VERSION ""

NS_ :

BS_:

BU_: DataECU UDSnode04 UDSnode03 MyECU

BO_ 514 msg_com_data2_CAN2: 8 DataECU
 SG_ sig_com_data2_CAN2 : 0|64@1+ (1,0) [0|1.84467440737096E+019] ""  MyECU

BO_ 513 msg_com_data1_CAN2: 8 DataECU
 SG_ sig_com_data1_CAN2 : 0|64@1+ (1,0) [0|1.84467440737096E+019] ""  MyECU

BO_ 1632 msg_diag_response_UDSnode04: 8 UDSnode04
 SG_ sig_diag_response_UDSnode04 : 0|8@1+ (1,0) [0|255] ""  MyECU

BO_ 1616 msg_diag_response_UDSnode03: 8 UDSnode03
 SG_ sig_diag_response_UDSnode03 : 0|8@1+ (1,0) [0|255] ""  MyECU

BO_ 1634 msg_diag_request_UDSnode04: 8 MyECU
 SG_ sig_diag_request_UDSnode04 : 0|8@1+ (1,0) [0|255] ""  UDSnode04

BO_ 1618 msg_diag_request_UDSnode03: 8 MyECU
 SG_ sig_diag_request_UDSnode03 : 0|8@1+ (1,0) [0|255] ""  UDSnode03

BO_ 1790 msg_diag_request_func_CAN2: 8 MyECU
 SG_ sig_diag_request_func_CAN2 : 0|8@1+ (1,0) [0|255] ""  UDSnode04,UDSnode03

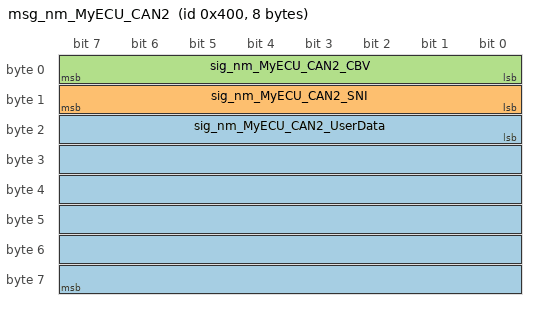
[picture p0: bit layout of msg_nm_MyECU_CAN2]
BO_ 1024 msg_nm_MyECU_CAN2: 8 MyECU
 SG_ sig_nm_MyECU_CAN2_UserData : 16|48@1+ (1,0) [0|281474976710655] ""  DataECU
 SG_ sig_nm_MyECU_CAN2_SNI : 8|8@1+ (1,0) [0|255] ""  DataECU
 SG_ sig_nm_MyECU_CAN2_CBV : 0|8@1+ (1,0) [0|255] ""  DataECU

BA_DEF_ BO_  "DiagConnection" INT 0 65535;
BA_DEF_  "DBName" STRING ;
BA_DEF_ BO_  "GenMsgCycleTime" INT 0 0;
BA_DEF_ BO_  "GenMsgSendType" ENUM  "Cyclic","NotUsed","NotUsed","NotUsed","NotUsed","NotUsed","NotUsed","IfActive","NoMsgSendType","NotUsed";
BA_DEF_ SG_  "GenSigCycleTimeActive" INT 0 0;
BA_DEF_ SG_  "GenSigCycleTime" INT 0 0;
BA_DEF_ SG_  "GenSigSendType" ENUM  "Cyclic","OnWrite","OnWriteWithRepetition","OnChange","OnChangeWithRepetition","IfActive","IfActiveWithRepetition","NoSigSendType","OnChangeAndIfActive","OnChangeAndIfActiveWithRepetition";
BA_DEF_  "Baudrate" INT 0 1000000;
BA_DEF_  "BusType" STRING ;
BA_DEF_  "NmType" STRING ;
BA_DEF_  "Manufacturer" STRING ;
BA_DEF_  "NmAsrWaitBusSleepTime" INT 0 65535;
BA_DEF_  "NmAsrTimeoutTime" INT 0 65535;
BA_DEF_  "NmAsrRepeatMessageTime" INT 0 65535;
BA_DEF_ BU_  "NmAsrNode" ENUM  "no","yes";
BA_DEF_  "NmAsrMessageCount" INT 0 256;
BA_DEF_ BO_  "NmAsrMessage" ENUM  "no","yes";
BA_DEF_ BU_  "NmAsrCanMsgReducedTime" INT 0 65535;
BA_DEF_  "NmAsrCanMsgCycleTime" INT 0 65535;
BA_DEF_  "NmAsrBaseAddress" HEX 0 65535;
BA_DEF_ BU_  "ILUsed" ENUM  "no","yes";
BA_DEF_ BO_  "GenMsgILSupport" ENUM  "no","yes";
BA_DEF_ BO_  "DiagState" ENUM  "No","Yes";
BA_DEF_ BO_  "DiagResponse" ENUM  "No","Yes";
BA_DEF_ BO_  "DiagRequest" ENUM  "No","Yes";
BA_DEF_DEF_  "DiagConnection" 0;
BA_DEF_DEF_  "DBName" "";
BA_DEF_DEF_  "GenMsgCycleTime" 0;
BA_DEF_DEF_  "GenMsgSendType" "NoMsgSendType";
BA_DEF_DEF_  "GenSigCycleTimeActive" 0;
BA_DEF_DEF_  "GenSigCycleTime" 0;
BA_DEF_DEF_  "GenSigSendType" "Cyclic";
BA_DEF_DEF_  "Baudrate" 500000;
BA_DEF_DEF_  "BusType" "";
BA_DEF_DEF_  "NmType" "";
BA_DEF_DEF_  "Manufacturer" "Vector";
BA_DEF_DEF_  "NmAsrWaitBusSleepTime" 750;
BA_DEF_DEF_  "NmAsrTimeoutTime" 1000;
BA_DEF_DEF_  "NmAsrRepeatMessageTime" 400;
BA_DEF_DEF_  "NmAsrNode" "yes";
BA_DEF_DEF_  "NmAsrMessageCount" 64;
BA_DEF_DEF_  "NmAsrMessage" "no";
BA_DEF_DEF_  "NmAsrCanMsgReducedTime" 50;
BA_DEF_DEF_  "NmAsrCanMsgCycleTime" 100;
BA_DEF_DEF_  "NmAsrBaseAddress" 1024;
BA_DEF_DEF_  "ILUsed" "yes";
BA_DEF_DEF_  "GenMsgILSupport" "yes";
BA_DEF_DEF_  "DiagState" "No";
BA_DEF_DEF_  "DiagResponse" "No";
BA_DEF_DEF_  "DiagRequest" "No";
BA_ "NmAsrCanMsgCycleTime" 800;
BA_ "NmAsrWaitBusSleepTime" 900;
BA_ "BusType" "CAN";
BA_ "NmType" "NmAsr";
BA_ "DBName" "CAN2";
BA_ "DiagConnection" BO_ 1632 14;
BA_ "DiagResponse" BO_ 1632 1;
BA_ "DiagConnection" BO_ 1616 13;
BA_ "DiagResponse" BO_ 1616 1;
BA_ "DiagConnection" BO_ 1634 14;
BA_ "DiagRequest" BO_ 1634 1;
BA_ "DiagConnection" BO_ 1618 13;
BA_ "DiagRequest" BO_ 1618 1;
BA_ "DiagConnection" BO_ 1790 254;
BA_ "DiagState" BO_ 1790 1;
BA_ "GenMsgCycleTime" BO_ 1024 100;
BA_ "GenMsgSendType" BO_ 1024 0;
BA_ "NmAsrMessage" BO_ 1024 1;
BA_ "GenMsgILSupport" BO_ 1024 0;
BA_ "GenSigSendType" SG_ 514 sig_com_data2_CAN2 7;
BA_ "GenSigSendType" SG_ 513 sig_com_data1_CAN2 7;
BA_ "GenSigSendType" SG_ 1632 sig_diag_response_UDSnode04 7;
BA_ "GenSigSendType" SG_ 1616 sig_diag_response_UDSnode03 7;
BA_ "GenSigSendType" SG_ 1634 sig_diag_request_UDSnode04 7;
BA_ "GenSigSendType" SG_ 1618 sig_diag_request_UDSnode03 7;
BA_ "GenSigSendType" SG_ 1790 sig_diag_request_func_CAN2 7;
BA_ "GenSigCycleTime" SG_ 1024 sig_nm_MyECU_CAN2_UserData 100;
BA_ "GenSigCycleTimeActive" SG_ 1024 sig_nm_MyECU_CAN2_UserData 100;
BA_ "GenSigCycleTimeActive" SG_ 1024 sig_nm_MyECU_CAN2_SNI 100;
BA_ "GenSigCycleTime" SG_ 1024 sig_nm_MyECU_CAN2_SNI 100;
BA_ "GenSigCycleTimeActive" SG_ 1024 sig_nm_MyECU_CAN2_CBV 100;
BA_ "GenSigCycleTime" SG_ 1024 sig_nm_MyECU_CAN2_CBV 100;
